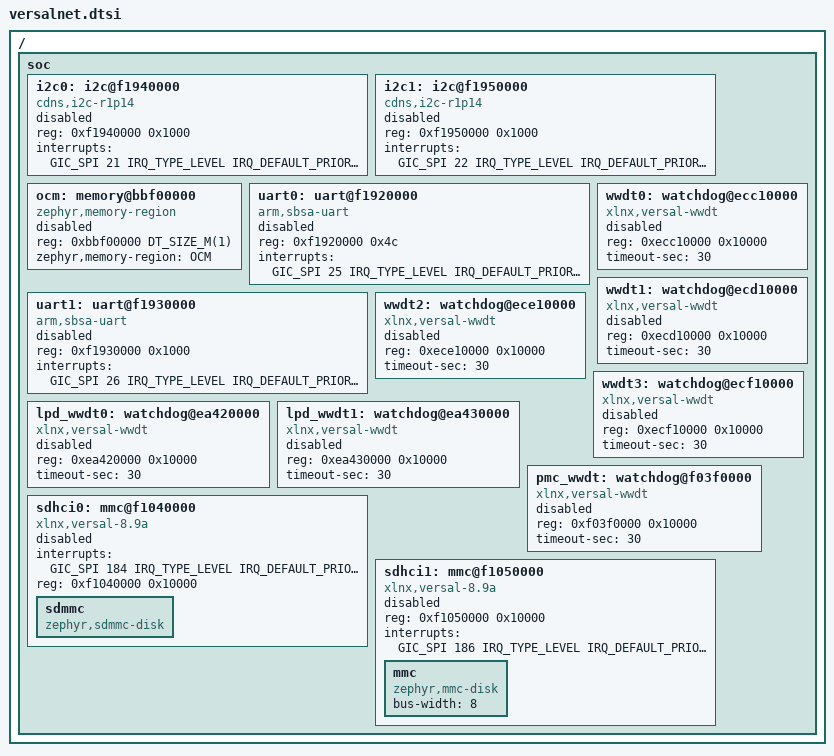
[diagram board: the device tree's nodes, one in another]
// SPDX-License-Identifier: GPL-2.0
/*
 * (C) Copyright 2025, Advanced Micro Devices, Inc.
 *
 * Mubin Sayyed <mubin.sayyed@amd.com>
 */

/ {
	soc: soc {
		i2c0: i2c@f1940000 {
			compatible = "cdns,i2c-r1p14";
			reg = <0xf1940000 0x1000>;
			status = "disabled";
			interrupts = <GIC_SPI 21 IRQ_TYPE_LEVEL IRQ_DEFAULT_PRIORITY>;
			#address-cells = <1>;
			#size-cells = <0>;
		};

		i2c1: i2c@f1950000 {
			compatible = "cdns,i2c-r1p14";
			reg = <0xf1950000 0x1000>;
			status = "disabled";
			interrupts = <GIC_SPI 22 IRQ_TYPE_LEVEL IRQ_DEFAULT_PRIORITY>;
			#address-cells = <1>;
			#size-cells = <0>;
		};

		ocm: memory@bbf00000 {
			compatible = "zephyr,memory-region";
			reg = <0xbbf00000 DT_SIZE_M(1)>;
			status = "disabled";
			zephyr,memory-region = "OCM";
		};

		uart0: uart@f1920000 {
			compatible = "arm,sbsa-uart";
			reg = <0xf1920000 0x4c>;
			status = "disabled";
			interrupt-names = "irq_0";
			interrupts = <GIC_SPI 25 IRQ_TYPE_LEVEL IRQ_DEFAULT_PRIORITY>;
		};

		uart1: uart@f1930000 {
			compatible = "arm,sbsa-uart";
			reg = <0xf1930000 0x1000>;
			status = "disabled";
			interrupt-names = "irq_1";
			interrupts = <GIC_SPI 26 IRQ_TYPE_LEVEL IRQ_DEFAULT_PRIORITY>;
		};

		wwdt0: watchdog@ecc10000 {
			compatible = "xlnx,versal-wwdt";
			status = "disabled";
			reg = <0xecc10000 0x10000>;
			timeout-sec = <30>;
		};

		wwdt1: watchdog@ecd10000 {
			compatible = "xlnx,versal-wwdt";
			status = "disabled";
			reg = <0xecd10000 0x10000>;
			timeout-sec = <30>;
		};

		wwdt2: watchdog@ece10000 {
			compatible = "xlnx,versal-wwdt";
			status = "disabled";
			reg = <0xece10000 0x10000>;
			timeout-sec = <30>;
		};

		wwdt3: watchdog@ecf10000 {
			compatible = "xlnx,versal-wwdt";
			status = "disabled";
			reg = <0xecf10000 0x10000>;
			timeout-sec = <30>;
		};

		lpd_wwdt0: watchdog@ea420000 {
			compatible = "xlnx,versal-wwdt";
			status = "disabled";
			reg = <0xea420000 0x10000>;
			timeout-sec = <30>;
		};

		lpd_wwdt1: watchdog@ea430000 {
			compatible = "xlnx,versal-wwdt";
			status = "disabled";
			reg = <0xea430000 0x10000>;
			timeout-sec = <30>;
		};

		pmc_wwdt: watchdog@f03f0000 {
			compatible = "xlnx,versal-wwdt";
			status = "disabled";
			reg = <0xf03f0000 0x10000>;
			timeout-sec = <30>;
		};

		sdhci0: mmc@f1040000 {
			compatible = "xlnx,versal-8.9a";
			status = "disabled";
			interrupts = <GIC_SPI 184 IRQ_TYPE_LEVEL IRQ_DEFAULT_PRIORITY>;
			reg = <0xf1040000 0x10000>;
			sdmmc {
				compatible = "zephyr,sdmmc-disk";
			};
		};

		sdhci1: mmc@f1050000 {
			compatible = "xlnx,versal-8.9a";
			status = "disabled";
			reg = <0xf1050000 0x10000>;
			interrupts = <GIC_SPI 186 IRQ_TYPE_LEVEL IRQ_DEFAULT_PRIORITY>;
			mmc {
				bus-width = <8>;
				compatible = "zephyr,mmc-disk";
			};
		};
	};
};
